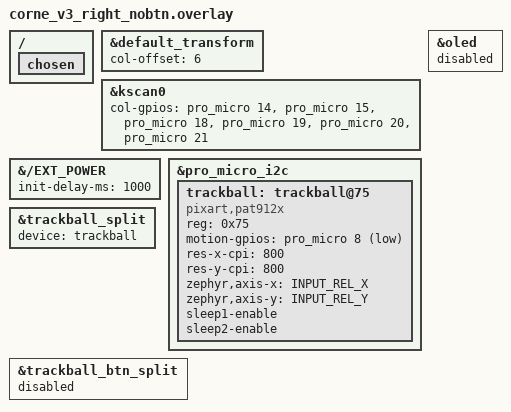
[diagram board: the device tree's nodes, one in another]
/*
 * Right without trackball button (D10 / NFC pin).
 * Matrix + PAT912x only — bisect if full right still kills keys after NFC UICR.
 */

#include "corne_v3.dtsi"

&default_transform {
	col-offset = <6>;
};

&kscan0 {
	col-gpios
		= <&pro_micro 14 GPIO_ACTIVE_HIGH>
		, <&pro_micro 15 GPIO_ACTIVE_HIGH>
		, <&pro_micro 18 GPIO_ACTIVE_HIGH>
		, <&pro_micro 19 GPIO_ACTIVE_HIGH>
		, <&pro_micro 20 GPIO_ACTIVE_HIGH>
		, <&pro_micro 21 GPIO_ACTIVE_HIGH>
		;
};

&oled {
	status = "disabled";
};

/ {
	chosen {
		/delete-property/ zephyr,display;
	};
};

&{/EXT_POWER} {
	init-delay-ms = <1000>;
};

&pro_micro_i2c {
	trackball: trackball@75 {
		compatible = "pixart,pat912x";
		reg = <0x75>;
		status = "okay";

		motion-gpios = <&pro_micro 8 (GPIO_ACTIVE_LOW | GPIO_PULL_UP)>;

		res-x-cpi = <800>;
		res-y-cpi = <800>;

		zephyr,axis-x = <INPUT_REL_X>;
		zephyr,axis-y = <INPUT_REL_Y>;

		sleep1-enable;
		sleep2-enable;
	};
};

&trackball_split {
	device = <&trackball>;
};

&trackball_btn_split {
	status = "disabled";
};
